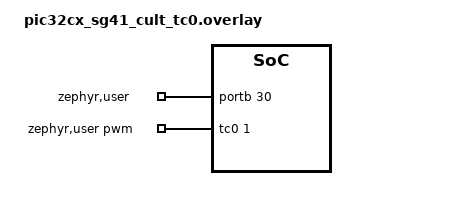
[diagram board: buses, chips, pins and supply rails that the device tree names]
/*
 * SPDX-FileCopyrightText: Copyright 2026 Microchip Technology Inc.
 * SPDX-License-Identifier: Apache-2.0
 */

/* connect PB31 to PB30 */

#define PWM_NODE    tc0
#define PWM_PINCTRL tc0_pwm_default
#include "mchp_pwm_loopback_support.dtsi"

/ {
	zephyr,user {
		pwms = <&tc0 1 PWM_MSEC(20) 0>;
		gpios = <&portb 30 GPIO_ACTIVE_HIGH>;
	};
};

&portb {
	status = "okay";
};

&pinctrl {
	tc0_pwm_default: tc0_pwm_default {
		group1 {
			pinmux = <PB31E_TC0_WO1>;
		};
	};
};
